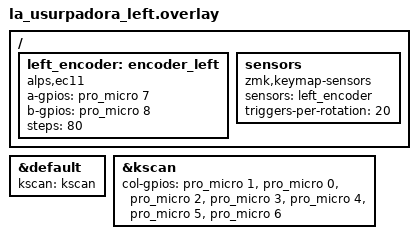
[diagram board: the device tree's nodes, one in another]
#include "la_usurpadora.dtsi"

/ {
    left_encoder: encoder_left {
        compatible = "alps,ec11";
        a-gpios = <&pro_micro 7 (GPIO_ACTIVE_HIGH | GPIO_PULL_UP)>; 
        b-gpios = <&pro_micro 8 (GPIO_ACTIVE_HIGH | GPIO_PULL_UP)>; 
        steps = <80>; 
    };

    sensors: sensors {
        compatible = "zmk,keymap-sensors";
        sensors = <&left_encoder>;
        triggers-per-rotation = <20>;
    };
};

&default {
    kscan = <&kscan>;
};

&kscan {
    col-gpios
        = <&pro_micro 1 GPIO_ACTIVE_HIGH> 
        , <&pro_micro 0 GPIO_ACTIVE_HIGH> 
        , <&pro_micro 2 GPIO_ACTIVE_HIGH> 
        , <&pro_micro 3 GPIO_ACTIVE_HIGH> 
        , <&pro_micro 4 GPIO_ACTIVE_HIGH> 
        , <&pro_micro 5 GPIO_ACTIVE_HIGH> 
        , <&pro_micro 6 GPIO_ACTIVE_HIGH>
        ;
};
